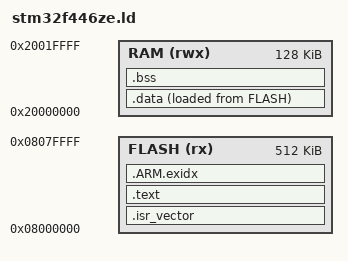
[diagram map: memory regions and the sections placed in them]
/* SPDX-License-Identifier: Apache-2.0 */
/* Copyright 2026 Junior Deogracias */
/* STM32F446ZE: 512 KiB of flash at 0x08000000, 128 KiB of SRAM (SRAM1 112 KiB and SRAM2 16 KiB) at 0x20000000 */
MEMORY
{
    FLASH (rx) : ORIGIN = 0x08000000, LENGTH = 512K
    RAM (rwx)  : ORIGIN = 0x20000000, LENGTH = 128K
}
ENTRY(Reset_Handler)
_estack = ORIGIN(RAM) + LENGTH(RAM);
SECTIONS
{
    .isr_vector : { KEEP(*(.isr_vector)) } > FLASH
    .text : { *(.text*) *(.rodata*) . = ALIGN(4); } > FLASH
    .ARM.exidx : { *(.ARM.exidx*) } > FLASH
    _sidata = LOADADDR(.data);
    .data : { _sdata = .; *(.data*) . = ALIGN(4); _edata = .; } > RAM AT > FLASH
    .bss (NOLOAD) : { _sbss = .; *(.bss*) *(COMMON) . = ALIGN(4); _ebss = .; } > RAM
}
